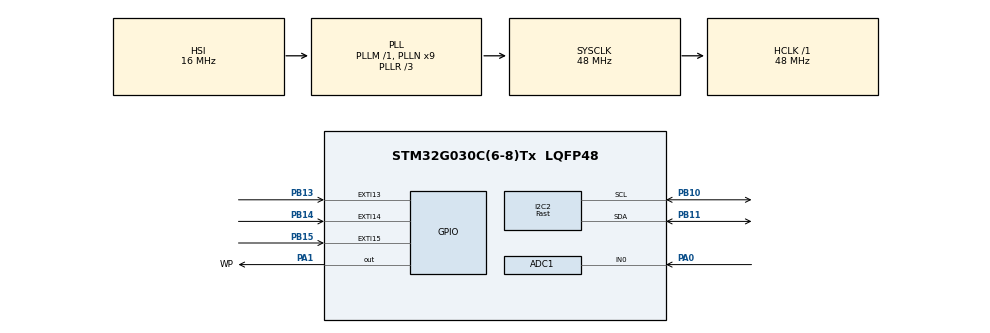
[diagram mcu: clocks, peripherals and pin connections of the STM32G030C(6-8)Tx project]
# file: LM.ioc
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ADC1.Channel-3\#ChannelRegularConversion=ADC_CHANNEL_0
ADC1.NbrOfConversionFlag=1
ADC1.Rank-3\#ChannelRegularConversion=1
ADC1.SamplingTime-3\#ChannelRegularConversion=ADC_SAMPLINGTIME_COMMON_1
ADC1.SelectedChannel=ADC_CHANNEL_0
ADC1.master=1
I2C2.I2C_Speed_Mode=I2C_Fast
I2C2.Timing=0x2010091A
Mcu.Family=STM32G0
Mcu.Name=STM32G030C(6-8)Tx
Mcu.Package=LQFP48
NVIC.EXTI4_15_IRQn=true\:0\:0\:false\:false\:true\:true\:true\:true
PA0.Mode=IN0
PA0.Signal=ADC1_IN0
PA1.GPIO_Label=WP
PA1.Signal=GPIO_Output
PA13.Mode=Serial_Wire
PA13.Signal=SYS_SWDIO
PA14-BOOT0.Mode=Serial_Wire
PA14-BOOT0.Signal=SYS_SWCLK
PB10.Mode=I2C
PB10.Signal=I2C2_SCL
PB11.Mode=I2C
PB11.Signal=I2C2_SDA
PB13.GPIO_PuPd=GPIO_PULLUP
PB13.Signal=GPXTI13
PB14.GPIO_PuPd=GPIO_PULLUP
PB14.Signal=GPXTI14
PB15.GPIO_PuPd=GPIO_PULLUP
PB15.Signal=GPXTI15
ProjectManager.HeapSize=0x200
ProjectManager.StackSize=0x400
ProjectManager.TargetToolchain=STM32CubeIDE
RCC.ADCFreq_Value=48000000
RCC.AHBFreq_Value=48000000
RCC.CortexFreq_Value=48000000
RCC.EXTERNAL_CLOCK_VALUE=12288000
RCC.HCLKFreq_Value=48000000
RCC.HSE_VALUE=8000000
RCC.HSI_VALUE=16000000
RCC.LSE_VALUE=32768
RCC.PLLN=9
RCC.PLLR=RCC_PLLR_DIV3
RCC.SYSCLKFreq_VALUE=48000000
RCC.SYSCLKSource=RCC_SYSCLKSOURCE_PLLCLK
RCC.VCOOutputFreq_Value=144000000
board=custom

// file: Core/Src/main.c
/* USER CODE BEGIN Header */
/**
  ******************************************************************************
  * @file           : main.c
  * @brief          : Main program body
  ******************************************************************************
  * @attention
  *
  * Copyright (c) 2024 STMicroelectronics.
  * All rights reserved.
  *
  * This software is licensed under terms that can be found in the LICENSE file
  * in the root directory of this software component.
  * If no LICENSE file comes with this software, it is provided AS-IS.
  *
  ******************************************************************************
  */
/* USER CODE END Header */
#include "main.h"
#include "Light_meter.h"

ADC_HandleTypeDef hadc1;

I2C_HandleTypeDef hi2c2;

void SystemClock_Config(void);
static void MX_GPIO_Init(void);
static void MX_I2C2_Init(void);
static void MX_ADC1_Init(void);

int main(void)
{

  /* MCU Configuration--------------------------------------------------------*/

  /* Reset of all peripherals, Initializes the Flash interface and the Systick. */
  HAL_Init();

  /* Configure the system clock */
  SystemClock_Config();

  /* Initialize all configured peripherals */
  MX_GPIO_Init();
  MX_I2C2_Init();
  MX_ADC1_Init();

  /* USER CODE BEGIN 2 */
  LM_Init();
  /* USER CODE END 2 */

  /* Infinite loop */
  while (1)
  {
	  Loop();
  }
}

void SystemClock_Config(void)
{
  RCC_OscInitTypeDef RCC_OscInitStruct = {0};
  RCC_ClkInitTypeDef RCC_ClkInitStruct = {0};

  /** Configure the main internal regulator output voltage
  */
  HAL_PWREx_ControlVoltageScaling(PWR_REGULATOR_VOLTAGE_SCALE1);

  /** Initializes the RCC Oscillators according to the specified parameters
  * in the RCC_OscInitTypeDef structure.
  */
  RCC_OscInitStruct.OscillatorType = RCC_OSCILLATORTYPE_HSI;
  RCC_OscInitStruct.HSIState = RCC_HSI_ON;
  RCC_OscInitStruct.HSIDiv = RCC_HSI_DIV1;
  RCC_OscInitStruct.HSICalibrationValue = RCC_HSICALIBRATION_DEFAULT;
  RCC_OscInitStruct.PLL.PLLState = RCC_PLL_ON;
  RCC_OscInitStruct.PLL.PLLSource = RCC_PLLSOURCE_HSI;
  RCC_OscInitStruct.PLL.PLLM = RCC_PLLM_DIV1;
  RCC_OscInitStruct.PLL.PLLN = 9;
  RCC_OscInitStruct.PLL.PLLP = RCC_PLLP_DIV2;
  RCC_OscInitStruct.PLL.PLLR = RCC_PLLR_DIV3;
  if (HAL_RCC_OscConfig(&RCC_OscInitStruct) != HAL_OK)
  {
    Error_Handler();
  }

  /** Initializes the CPU, AHB and APB buses clocks
  */
  RCC_ClkInitStruct.ClockType = RCC_CLOCKTYPE_HCLK|RCC_CLOCKTYPE_SYSCLK
                              |RCC_CLOCKTYPE_PCLK1;
  RCC_ClkInitStruct.SYSCLKSource = RCC_SYSCLKSOURCE_PLLCLK;
  RCC_ClkInitStruct.AHBCLKDivider = RCC_SYSCLK_DIV1;
  RCC_ClkInitStruct.APB1CLKDivider = RCC_HCLK_DIV1;

  if (HAL_RCC_ClockConfig(&RCC_ClkInitStruct, FLASH_LATENCY_1) != HAL_OK)
  {
    Error_Handler();
  }
}

static void MX_ADC1_Init(void)
{

  ADC_ChannelConfTypeDef sConfig = {0};

  /** Configure the global features of the ADC (Clock, Resolution, Data Alignment and number of conversion)
  */
  hadc1.Instance = ADC1;
  hadc1.Init.ClockPrescaler = ADC_CLOCK_SYNC_PCLK_DIV2;
  hadc1.Init.Resolution = ADC_RESOLUTION_12B;
  hadc1.Init.DataAlign = ADC_DATAALIGN_RIGHT;
  hadc1.Init.ScanConvMode = ADC_SCAN_DISABLE;
  hadc1.Init.EOCSelection = ADC_EOC_SINGLE_CONV;
  hadc1.Init.LowPowerAutoWait = DISABLE;
  hadc1.Init.LowPowerAutoPowerOff = DISABLE;
  hadc1.Init.ContinuousConvMode = DISABLE;
  hadc1.Init.NbrOfConversion = 1;
  hadc1.Init.DiscontinuousConvMode = DISABLE;
  hadc1.Init.ExternalTrigConv = ADC_SOFTWARE_START;
  hadc1.Init.ExternalTrigConvEdge = ADC_EXTERNALTRIGCONVEDGE_NONE;
  hadc1.Init.DMAContinuousRequests = DISABLE;
  hadc1.Init.Overrun = ADC_OVR_DATA_PRESERVED;
  hadc1.Init.SamplingTimeCommon1 = ADC_SAMPLETIME_1CYCLE_5;
  hadc1.Init.SamplingTimeCommon2 = ADC_SAMPLETIME_1CYCLE_5;
  hadc1.Init.OversamplingMode = DISABLE;
  hadc1.Init.TriggerFrequencyMode = ADC_TRIGGER_FREQ_HIGH;
  if (HAL_ADC_Init(&hadc1) != HAL_OK)
  {
    Error_Handler();
  }

  /** Configure Regular Channel
  */
  sConfig.Channel = ADC_CHANNEL_0;
  sConfig.Rank = ADC_REGULAR_RANK_1;
  sConfig.SamplingTime = ADC_SAMPLINGTIME_COMMON_1;
  if (HAL_ADC_ConfigChannel(&hadc1, &sConfig) != HAL_OK)
  {
    Error_Handler();
  }

}

static void MX_I2C2_Init(void)
{

  hi2c2.Instance = I2C2;
  hi2c2.Init.Timing = 0x2010091A;
  hi2c2.Init.OwnAddress1 = 0;
  hi2c2.Init.AddressingMode = I2C_ADDRESSINGMODE_7BIT;
  hi2c2.Init.DualAddressMode = I2C_DUALADDRESS_DISABLE;
  hi2c2.Init.OwnAddress2 = 0;
  hi2c2.Init.OwnAddress2Masks = I2C_OA2_NOMASK;
  hi2c2.Init.GeneralCallMode = I2C_GENERALCALL_DISABLE;
  hi2c2.Init.NoStretchMode = I2C_NOSTRETCH_DISABLE;
  if (HAL_I2C_Init(&hi2c2) != HAL_OK)
  {
    Error_Handler();
  }

  /** Configure Analogue filter
  */
  if (HAL_I2CEx_ConfigAnalogFilter(&hi2c2, I2C_ANALOGFILTER_ENABLE) != HAL_OK)
  {
    Error_Handler();
  }

  /** Configure Digital filter
  */
  if (HAL_I2CEx_ConfigDigitalFilter(&hi2c2, 0) != HAL_OK)
  {
    Error_Handler();
  }

}

static void MX_GPIO_Init(void)
{
  GPIO_InitTypeDef GPIO_InitStruct = {0};

  /* GPIO Ports Clock Enable */
  __HAL_RCC_GPIOC_CLK_ENABLE();
  __HAL_RCC_GPIOF_CLK_ENABLE();
  __HAL_RCC_GPIOA_CLK_ENABLE();
  __HAL_RCC_GPIOB_CLK_ENABLE();
  __HAL_RCC_GPIOD_CLK_ENABLE();

  /*Configure GPIO pin Output Level */
  HAL_GPIO_WritePin(WP_GPIO_Port, WP_Pin, GPIO_PIN_RESET);

  /*Configure GPIO pins : PC13 PC14 PC15 PC6
                           PC7 */
  GPIO_InitStruct.Pin = GPIO_PIN_13|GPIO_PIN_14|GPIO_PIN_15|GPIO_PIN_6
                          |GPIO_PIN_7;
  GPIO_InitStruct.Mode = GPIO_MODE_ANALOG;
  GPIO_InitStruct.Pull = GPIO_NOPULL;
  HAL_GPIO_Init(GPIOC, &GPIO_InitStruct);

  /*Configure GPIO pins : PF0 PF1 */
  GPIO_InitStruct.Pin = GPIO_PIN_0|GPIO_PIN_1;
  GPIO_InitStruct.Mode = GPIO_MODE_ANALOG;
  GPIO_InitStruct.Pull = GPIO_NOPULL;
  HAL_GPIO_Init(GPIOF, &GPIO_InitStruct);

  /*Configure GPIO pin : WP_Pin */
  GPIO_InitStruct.Pin = WP_Pin;
  GPIO_InitStruct.Mode = GPIO_MODE_OUTPUT_PP;
  GPIO_InitStruct.Pull = GPIO_NOPULL;
  GPIO_InitStruct.Speed = GPIO_SPEED_FREQ_LOW;
  HAL_GPIO_Init(WP_GPIO_Port, &GPIO_InitStruct);

  /*Configure GPIO pins : PA2 PA3 PA4 PA5
                           PA6 PA7 PA8 PA9
                           PA10 PA11 PA12 PA15 */
  GPIO_InitStruct.Pin = GPIO_PIN_2|GPIO_PIN_3|GPIO_PIN_4|GPIO_PIN_5
                          |GPIO_PIN_6|GPIO_PIN_7|GPIO_PIN_8|GPIO_PIN_9
                          |GPIO_PIN_10|GPIO_PIN_11|GPIO_PIN_12|GPIO_PIN_15;
  GPIO_InitStruct.Mode = GPIO_MODE_ANALOG;
  GPIO_InitStruct.Pull = GPIO_NOPULL;
  HAL_GPIO_Init(GPIOA, &GPIO_InitStruct);

  /*Configure GPIO pins : PB0 PB1 PB2 PB12
                           PB3 PB4 PB5 PB6
                           PB7 PB8 PB9 */
  GPIO_InitStruct.Pin = GPIO_PIN_0|GPIO_PIN_1|GPIO_PIN_2|GPIO_PIN_12
                          |GPIO_PIN_3|GPIO_PIN_4|GPIO_PIN_5|GPIO_PIN_6
                          |GPIO_PIN_7|GPIO_PIN_8|GPIO_PIN_9;
  GPIO_InitStruct.Mode = GPIO_MODE_ANALOG;
  GPIO_InitStruct.Pull = GPIO_NOPULL;
  HAL_GPIO_Init(GPIOB, &GPIO_InitStruct);

  /*Configure GPIO pins : PB13 PB14 PB15 */
  GPIO_InitStruct.Pin = GPIO_PIN_13|GPIO_PIN_14|GPIO_PIN_15;
  GPIO_InitStruct.Mode = GPIO_MODE_IT_RISING;
  GPIO_InitStruct.Pull = GPIO_PULLUP;
  HAL_GPIO_Init(GPIOB, &GPIO_InitStruct);

  /*Configure GPIO pins : PD0 PD1 PD2 PD3 */
  GPIO_InitStruct.Pin = GPIO_PIN_0|GPIO_PIN_1|GPIO_PIN_2|GPIO_PIN_3;
  GPIO_InitStruct.Mode = GPIO_MODE_ANALOG;
  GPIO_InitStruct.Pull = GPIO_NOPULL;
  HAL_GPIO_Init(GPIOD, &GPIO_InitStruct);

  /* EXTI interrupt init*/
  HAL_NVIC_SetPriority(EXTI4_15_IRQn, 0, 0);
  HAL_NVIC_EnableIRQ(EXTI4_15_IRQn);

}

void Error_Handler(void)
{
  __disable_irq();
  while (1)
  {
  }
}
